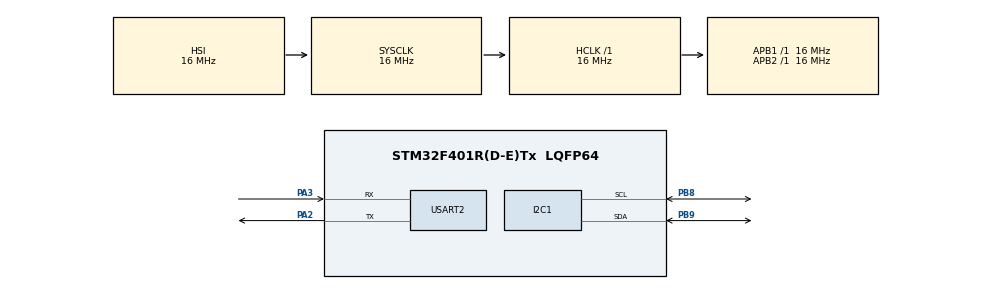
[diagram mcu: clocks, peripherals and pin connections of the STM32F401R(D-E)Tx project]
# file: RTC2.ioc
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Mcu.Family=STM32F4
Mcu.Name=STM32F401R(D-E)Tx
Mcu.Package=LQFP64
NVIC.PriorityGroup=NVIC_PRIORITYGROUP_4
PA2.Mode=Asynchronous
PA2.Signal=USART2_TX
PA3.Mode=Asynchronous
PA3.Signal=USART2_RX
PB8.Mode=I2C
PB8.Signal=I2C1_SCL
PB9.Mode=I2C
PB9.Signal=I2C1_SDA
PH0\ -\ OSC_IN.Mode=HSE-External-Oscillator
PH0\ -\ OSC_IN.Signal=RCC_OSC_IN
PH1\ -\ OSC_OUT.Mode=HSE-External-Oscillator
PH1\ -\ OSC_OUT.Signal=RCC_OSC_OUT
ProjectManager.HeapSize=0x200
ProjectManager.StackSize=0x400
ProjectManager.TargetToolchain=STM32CubeIDE
RCC.AHBFreq_Value=16000000
RCC.APB1Freq_Value=16000000
RCC.APB2Freq_Value=16000000
RCC.CortexFreq_Value=16000000
RCC.HSE_VALUE=25000000
RCC.HSI_VALUE=16000000
RCC.LSE_VALUE=32768
RCC.SYSCLKFreq_VALUE=16000000
RCC.VCOOutputFreq_Value=192000000
USART2.VirtualMode=VM_ASYNC
board=custom

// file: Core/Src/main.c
/* USER CODE BEGIN Header */
/**
  ******************************************************************************
  * @file           : main.c
  * @brief          : Main program body
  ******************************************************************************
  * @attention
  *
  * <h2><center>&copy; Copyright (c) 2019 STMicroelectronics.
  * All rights reserved.</center></h2>
  *
  * This software component is licensed by ST under BSD 3-Clause license,
  * the "License"; You may not use this file except in compliance with the
  * License. You may obtain a copy of the License at:
  *                        opensource.org/licenses/BSD-3-Clause
  *
  ******************************************************************************
  */
/* USER CODE END Header */

#include "main.h"

/* USER CODE BEGIN Includes */
#include <stdio.h>
#include "retarget.h"
#include "rtc.h"
/* USER CODE END Includes */

I2C_HandleTypeDef hi2c1;

UART_HandleTypeDef huart2;

void SystemClock_Config(void);
static void MX_GPIO_Init(void);
static void MX_I2C1_Init(void);
static void MX_USART2_UART_Init(void);

int main(void)
{

  /* MCU Configuration--------------------------------------------------------*/

  /* Reset of all peripherals, Initializes the Flash interface and the Systick. */
  HAL_Init();

  /* Configure the system clock */
  SystemClock_Config();

  /* Initialize all configured peripherals */
  MX_GPIO_Init();
  MX_I2C1_Init();
  MX_USART2_UART_Init();
  /* USER CODE BEGIN 2 */
  RetargetInit(&huart2);
  printf("init\r\n");
  /* USER CODE END 2 */

  /* Infinite loop */
  /* USER CODE BEGIN WHILE */
  WriteRTC(0,20,16,5,6,12,2019);
  while (1)
  {
    /* USER CODE END WHILE */
	  /*I2Cflag = HAL_I2C_Master_Transmit(&hi2c1, RTC_ADDR, RTC_READ_ADDR, 1, HAL_MAX_DELAY);
	  if (I2Cflag!=HAL_OK)
	  {
		  printf("Writing Error\n\r");
		  HAL_Delay(500);
	  }
	  else
	  {
		  int8_t i;

		  I2Cflag = HAL_I2C_Master_Receive(&hi2c1, RTC_ADDR, timetest, 8, HAL_MAX_DELAY);
		  if (I2Cflag!=HAL_OK)
		  {
			  printf("Reading Error\n\r");
		  }

		  for (i=0;i<7;i++){
			  printf("%d ",BcdToDec(timetest[i]));
		  }
		  printf("\r\n");

	  }
	  HAL_Delay(500); */
    /* USER CODE BEGIN 3 */
	  ReadRTC();
	  HAL_Delay(1000);
  }
  /* USER CODE END 3 */
}

void SystemClock_Config(void)
{
  RCC_OscInitTypeDef RCC_OscInitStruct = {0};
  RCC_ClkInitTypeDef RCC_ClkInitStruct = {0};

  /** Configure the main internal regulator output voltage
  */
  __HAL_RCC_PWR_CLK_ENABLE();
  __HAL_PWR_VOLTAGESCALING_CONFIG(PWR_REGULATOR_VOLTAGE_SCALE2);
  /** Initializes the CPU, AHB and APB busses clocks
  */
  RCC_OscInitStruct.OscillatorType = RCC_OSCILLATORTYPE_HSI;
  RCC_OscInitStruct.HSIState = RCC_HSI_ON;
  RCC_OscInitStruct.HSICalibrationValue = RCC_HSICALIBRATION_DEFAULT;
  RCC_OscInitStruct.PLL.PLLState = RCC_PLL_NONE;
  if (HAL_RCC_OscConfig(&RCC_OscInitStruct) != HAL_OK)
  {
    Error_Handler();
  }
  /** Initializes the CPU, AHB and APB busses clocks
  */
  RCC_ClkInitStruct.ClockType = RCC_CLOCKTYPE_HCLK|RCC_CLOCKTYPE_SYSCLK
                              |RCC_CLOCKTYPE_PCLK1|RCC_CLOCKTYPE_PCLK2;
  RCC_ClkInitStruct.SYSCLKSource = RCC_SYSCLKSOURCE_HSI;
  RCC_ClkInitStruct.AHBCLKDivider = RCC_SYSCLK_DIV1;
  RCC_ClkInitStruct.APB1CLKDivider = RCC_HCLK_DIV1;
  RCC_ClkInitStruct.APB2CLKDivider = RCC_HCLK_DIV1;

  if (HAL_RCC_ClockConfig(&RCC_ClkInitStruct, FLASH_LATENCY_0) != HAL_OK)
  {
    Error_Handler();
  }
}

static void MX_I2C1_Init(void)
{

  /* USER CODE BEGIN I2C1_Init 0 */
	GPIO_InitTypeDef GPIO_InitStruct;
	__HAL_RCC_I2C1_CLK_ENABLE();
  /* USER CODE END I2C1_Init 0 */

  hi2c1.Instance = I2C1;
  hi2c1.Init.ClockSpeed = 100000;
  hi2c1.Init.DutyCycle = I2C_DUTYCYCLE_2;
  hi2c1.Init.OwnAddress1 = 0;
  hi2c1.Init.AddressingMode = I2C_ADDRESSINGMODE_7BIT;
  hi2c1.Init.DualAddressMode = I2C_DUALADDRESS_DISABLE;
  hi2c1.Init.OwnAddress2 = 0;
  hi2c1.Init.GeneralCallMode = I2C_GENERALCALL_DISABLE;
  hi2c1.Init.NoStretchMode = I2C_NOSTRETCH_DISABLE;

  GPIO_InitStruct.Pin = GPIO_PIN_8|GPIO_PIN_9;
  GPIO_InitStruct.Mode = GPIO_MODE_AF_OD;
  GPIO_InitStruct.Pull = GPIO_PULLUP;
  GPIO_InitStruct.Speed = GPIO_SPEED_FREQ_VERY_HIGH;
  GPIO_InitStruct.Alternate = GPIO_AF4_I2C1;
  HAL_GPIO_Init(GPIOB, &GPIO_InitStruct);
  if (HAL_I2C_Init(&hi2c1) != HAL_OK)
  {
    Error_Handler();
  }

}

static void MX_USART2_UART_Init(void)
{

  huart2.Instance = USART2;
  huart2.Init.BaudRate = 115200;
  huart2.Init.WordLength = UART_WORDLENGTH_8B;
  huart2.Init.StopBits = UART_STOPBITS_1;
  huart2.Init.Parity = UART_PARITY_NONE;
  huart2.Init.Mode = UART_MODE_TX_RX;
  huart2.Init.HwFlowCtl = UART_HWCONTROL_NONE;
  huart2.Init.OverSampling = UART_OVERSAMPLING_16;

  if (HAL_UART_Init(&huart2) != HAL_OK)
  {
    Error_Handler();
  }

}

static void MX_GPIO_Init(void)
{

  /* GPIO Ports Clock Enable */
  __HAL_RCC_GPIOH_CLK_ENABLE();
  __HAL_RCC_GPIOA_CLK_ENABLE();
  __HAL_RCC_GPIOB_CLK_ENABLE();

}

void Error_Handler(void)
{
}

/************************ (C) COPYRIGHT STMicroelectronics *****END OF FILE****/
